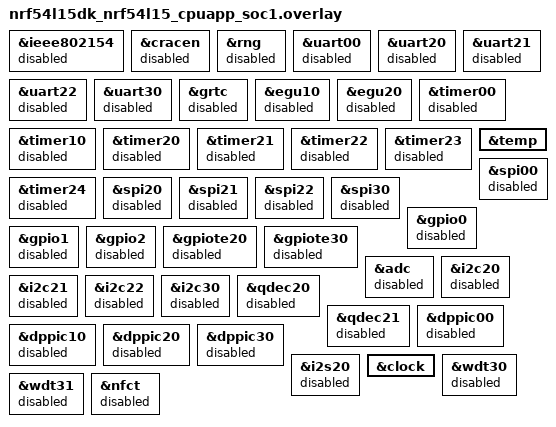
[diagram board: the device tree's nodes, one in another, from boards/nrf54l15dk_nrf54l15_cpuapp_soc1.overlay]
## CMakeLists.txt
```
# list(APPEND OVERLAY_CONFIG "debug.conf")
list(APPEND OVERLAY_CONFIG "dns.conf")
list(APPEND OVERLAY_CONFIG "secret.conf")
list(APPEND OVERLAY_CONFIG "thread-sed.conf")

cmake_minimum_required(VERSION 3.20.0)
find_package(Zephyr REQUIRED HINTS $ENV{ZEPHYR_BASE})

execute_process(COMMAND git describe
                WORKING_DIRECTORY ${CMAKE_CURRENT_SOURCE_DIR}
                OUTPUT_VARIABLE GIT_DESCRIBE
                ERROR_QUIET)
string(STRIP "${GIT_DESCRIBE}" GIT_DESCRIBE)
STRING(REGEX MATCH "[0-9]+\\.[0-9]+\\.[0-9]+"
       VERSION "${GIT_DESCRIBE}")

project(app LANGUAGES C VERSION ${VERSION})

configure_file(app_version.h.in ${CMAKE_BINARY_DIR}/app/include/app_version.h)
zephyr_include_directories(
    ${CMAKE_BINARY_DIR}/app/include
)

target_include_directories(app PRIVATE src)

target_sources(app PRIVATE
        src/main.c)

zephyr_include_directories(
    configuration/${BOARD}
)
```

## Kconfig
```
mainmenu "Thread Button Application"

config APP_MAIN_LOOP_PERIOD_SEC
	int "Main loop period (sec)"
	default 60
	help
	  Main loop period in seconds.

source "Kconfig.zephyr"
```

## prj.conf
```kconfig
CONFIG_APP_MAIN_LOOP_PERIOD_SEC=600

CONFIG_INPUT=y
CONFIG_SERIAL=y

CONFIG_HEAP_MEM_POOL_SIZE=2048

CONFIG_PM_DEVICE=y

CONFIG_MAIN_STACK_SIZE=4096
CONFIG_SYSTEM_WORKQUEUE_STACK_SIZE=2048
CONFIG_LOG_BUFFER_SIZE=16384

CONFIG_CAF=y
CONFIG_CAF_BUTTONS=y
CONFIG_CAF_BUTTONS_DEBOUNCE_INTERVAL=10
CONFIG_CAF_BUTTONS_POLARITY_INVERSED=y
CONFIG_NRFX_GPIOTE_NUM_OF_EVT_HANDLERS=1

CONFIG_MY_MODULE_BASE_RESET=y
CONFIG_MY_MODULE_BASE_UID=y

CONFIG_MY_MODULE_BASE_WATCHDOG=y
CONFIG_MY_MODULE_BASE_WATCHDOG_TIMEOUT_SEC=760

CONFIG_MY_MODULE_BASE_HOME_ASSISTANT=y
CONFIG_MY_MODULE_BASE_HA_DEVICE_NAME="Action Button"
CONFIG_MY_MODULE_BASE_HA_DEV_TYPE_ACTION_BUTTON=y
CONFIG_MY_MODULE_BASE_HA_MQTT_SERVER_HOSTNAME="home.home.arpa"
CONFIG_MY_MODULE_BASE_HA_OT_LATENCY_THREAD_STACK_SIZE=1024

CONFIG_BOARD_ENABLE_DCDC=y

CONFIG_THREAD_NAME=y
CONFIG_EVENTS=y
CONFIG_CONSOLE=y
CONFIG_UART_CONSOLE=y

CONFIG_ENTROPY_NRF5_THR_THRESHOLD=4
CONFIG_ENTROPY_NRF5_ISR_THRESHOLD=12

CONFIG_THREAD_ANALYZER=y
CONFIG_INPUT_LOG_LEVEL_DBG=y
CONFIG_INPUT_THREAD_STACK_SIZE=2048
CONFIG_LOG_SPEED=y
CONFIG_LOG=y
```

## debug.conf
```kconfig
CONFIG_OPENTHREAD_DEBUG=y
# CONFIG_OPENTHREAD_LOG_LEVEL_DEBG=y
# CONFIG_OPENTHREAD_L2_DEBUG=y
# CONFIG_OPENTHREAD_L2_DEBUG_DUMP_15_4=y
```

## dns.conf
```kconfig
CONFIG_DNS_SERVER_IP_ADDRESSES=y
CONFIG_DNS_SERVER1="fd04:2240::1"
```

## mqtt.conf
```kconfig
CONFIG_MQTT_LIB=y
CONFIG_MQTT_KEEPALIVE=600
```

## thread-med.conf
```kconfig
CONFIG_FPU=y

CONFIG_SYSTEM_WORKQUEUE_STACK_SIZE=2048

# CONFIG_NET_TCP_ISN_RFC6528 is not set

CONFIG_OPENTHREAD_CSL_RECEIVER=y
CONFIG_OPENTHREAD_SLAAC=y
CONFIG_OPENTHREAD_CHANNEL=15
CONFIG_OPENTHREAD_NETWORK_NAME="home"
CONFIG_OPENTHREAD_XPANID="42:24:00:00:00:00:10:00"
CONFIG_OPENTHREAD_MTD=y
CONFIG_OPENTHREAD_MTD_SED=y

CONFIG_NETWORKING=y
CONFIG_NET_L2_OPENTHREAD=y

CONFIG_NET_TCP=y
CONFIG_NET_BUF_TX_COUNT=64
CONFIG_NET_LOG=y
```

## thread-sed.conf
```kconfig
CONFIG_OPENTHREAD_CHANNEL=15
CONFIG_OPENTHREAD_NETWORK_NAME="home"
CONFIG_OPENTHREAD_XPANID="42:24:00:00:00:00:10:00"
CONFIG_OPENTHREAD_MTD_SED=y
```

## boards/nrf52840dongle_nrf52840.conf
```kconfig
CONFIG_GPIO=y
CONFIG_SOC_SERIES_NRF52X=y
CONFIG_SOC_NRF52840_QIAA=y
CONFIG_NFCT_PINS_AS_GPIOS=y
CONFIG_ARM_MPU=y
CONFIG_HW_STACK_PROTECTION=y
```

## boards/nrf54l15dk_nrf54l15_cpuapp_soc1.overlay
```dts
/ {

};

&ieee802154 {
	status = "disabled";
};
&cracen {
	status = "disabled";
};
&rng {
	status = "disabled";
};




&uart00 {
	status = "disabled";
};

&uart20 {
	status = "disabled";
};

&uart21 {
	status = "disabled";
};

&uart22 {
	status = "disabled";
};

&uart30 {
	status = "disabled";
};

&grtc {
	status = "disabled";
};

&egu10 {
	status = "disabled";
};

&egu20 {
	status = "disabled";
};

&timer00 {
	status = "disabled";
};

&timer10 {
	status = "disabled";
};

&timer20 {
	status = "disabled";
};

&timer21 {
	status = "disabled";
};

&timer22 {
	status = "disabled";
};

&timer23 {
	status = "disabled";
};

&timer24 {
	status = "disabled";
};

&temp {
	status = "okay";
};

&spi00 {
	status = "disabled";
};

&spi20 {
	status = "disabled";
};

&spi21 {
	status = "disabled";
};

&spi22 {
	status = "disabled";
};

&spi30 {
	status = "disabled";
};

&gpio0 {
	status = "disabled";
};

&gpio1 {
	status = "disabled";
};

&gpio2 {
	status = "disabled";
};

&gpiote20 {
	status = "disabled";
};

&gpiote30 {
	status = "disabled";
};

&adc {
	status = "disabled";
};

&i2c20 {
	status = "disabled";
};

&i2c21 {
	status = "disabled";
};

&i2c22 {
	status = "disabled";
};

&i2c30 {
	status = "disabled";
};

&qdec20 {
	status = "disabled";
};

&qdec21 {
	status = "disabled";
};

&dppic00 {
	status = "disabled";
};

&dppic10 {
	status = "disabled";
};

&dppic20 {
	status = "disabled";
};

&dppic30 {
	status = "disabled";
};

&i2s20 {
       status = "disabled";
};

&clock {
	status = "okay";
};

&wdt30 {
	status = "disabled";
};

&wdt31 {
	status = "disabled";
};

&nfct {
	status = "disabled";
};
```

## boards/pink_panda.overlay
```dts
/* Copyright (c) 2020 Nordic Semiconductor ASA
 *
 * SPDX-License-Identifier: LicenseRef-Nordic-5-Clause
 */

/ {
	/*
	* In some default configurations within the nRF Connect SDK,
	* e.g. on nRF52840, the chosen zephyr,entropy node is &cryptocell.
	* This devicetree overlay ensures that default is overridden wherever it
	* is set, as this application uses the RNG node for entropy exclusively.
	*/
	chosen {
		zephyr,entropy = &rng;
	};
	// buttons: gpio-keys0 {
    //         compatible = "zephyr,gpio-keys";
    //         debounce-interval-ms = <30>;

    //         action_button: button_0 {
    //                 gpios = <&gpio0 25 (GPIO_PULL_UP | GPIO_ACTIVE_LOW)>;
    //                 zephyr,code = <10>;
    //         };
    // };
};
&adc {
	status = "disabled";
};
&uart1 {
	status = "disabled";
};
&pwm0 {
	status = "disabled";
};
&i2c0 {
	status = "disabled";
};
&spi0 {
	status = "disabled";
};
&spi1 {
	status = "disabled";
};
&spi2 {
	status = "disabled";
};
&spi3 {
	status = "disabled";
};
&qspi {
	status = "disabled";
};
&usbd {
	status = "disabled";
};
&gpio0 {
	status = "okay";
};
&gpio1 {
	status = "disabled";
};
&gpiote {
    status = "okay";
};
&ieee802154 {
	status = "okay";
};
```

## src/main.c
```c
#include <app_event_manager.h>
#include <hal/nrf_power.h>
#include <zephyr/drivers/gpio.h>
#include <zephyr/drivers/watchdog.h>
#include <zephyr/input/input.h>
#include <zephyr/pm/device.h>
// There is an include missing in thread_analyzer.h
// Workaround by including it lower.
#include <zephyr/debug/thread_analyzer.h>
#include <zephyr/sys/reboot.h>

#include <zephyr/logging/log.h>
LOG_MODULE_REGISTER(main, LOG_LEVEL_DBG);

#define MODULE main
#include <caf/events/module_state_event.h>
#include <caf/events/button_event.h>

#include <app_version.h>
#include <ha.h>
#include <mqtt.h>
#include <openthread.h>
#include <reset.h>
#include <uid.h>
#include <watchdog.h>



#define RETRY_DELAY_SECONDS			10

#define MAIN_LOOP_PERIOD_SECONDS		CONFIG_APP_MAIN_LOOP_PERIOD_SEC
#define NUMBER_OF_LOOP_RUN_ANALYSIS		((2 * MAIN_LOOP_PERIOD_SECONDS) / MAIN_LOOP_PERIOD_SECONDS)
#define NUMBER_OF_LOOP_RESET_WATCHDOG_SENSOR	((2 * MAIN_LOOP_PERIOD_SECONDS) / MAIN_LOOP_PERIOD_SECONDS)

#define SUSPEND_CONSOLE				1

#define ERROR_BOOT_TOKEN			(uint8_t)0x38


// static const struct device *const buttons_dev = DEVICE_DT_GET(DT_NODELABEL(buttons));
static bool ready = false;

static struct ha_sensor watchdog_triggered_sensor = {
	.type = HA_BINARY_SENSOR_TYPE,
	.name = "Watchdog",
	.device_class = "problem",
	.retain = true,
};

static struct ha_trigger trigger1 = {
	.type = "button_short_press",
	.subtype = "button_1",
};


int main(void)
{
	const struct device *wdt = DEVICE_DT_GET(DT_NODELABEL(wdt0));
	const struct device *cons = DEVICE_DT_GET(DT_CHOSEN(zephyr_console));

	int ret;
	int main_wdt_chan_id = -1, mqtt_wdt_chan_id = -1;
	uint32_t reset_cause;
	bool fast_boot = false;

	uint32_t main_loop_counter = 0;


	ret = watchdog_new_channel(wdt, &main_wdt_chan_id);
	if (ret < 0) {
		LOG_ERR("Could allocate main watchdog channel");
		return ret;
	}

	ret = watchdog_new_channel(wdt, &mqtt_wdt_chan_id);
	if (ret < 0) {
		LOG_ERR("Could allocate main watchdog channel");
		return ret;
	}

	ret = watchdog_start(wdt);
	if (ret < 0) {
		LOG_ERR("Could allocate start watchdog");
		return ret;
	}

	LOG_INF("\n\n🚀 MAIN START (%s) 🚀\n", APP_VERSION_FULL);

	reset_cause = show_reset_cause();
	clear_reset_cause();

	if (is_reset_cause_watchdog(reset_cause)
	    || is_reset_cause_button(reset_cause)) {
		ret = openthread_erase_persistent_info();
		if (ret < 0) {
			LOG_WRN("Could not erase openthread info");
		}
	}
	else if (is_reset_cause_software(reset_cause)
		 && nrf_power_gpregret_get(NRF_POWER, 0) == ERROR_BOOT_TOKEN) {
		LOG_INF("🔥 Fast boot!");
		fast_boot = true;
	}

	ret = openthread_my_start();
	if (ret < 0) {
		LOG_ERR("Could not start openthread");
		return ret;
	}

	ret = uid_init();
	if (ret < 0) {
		LOG_ERR("Could not init uid module");
		return ret;
	}

	ret = uid_generate_unique_id(watchdog_triggered_sensor.unique_id,
				     sizeof(watchdog_triggered_sensor.unique_id),
				     "nrf52840", "wdt",
				     uid_get_device_id());
	if (ret < 0) {
		LOG_ERR("Could not generate watchdog unique id");
		return ret;
	}

	if (app_event_manager_init()) {
		LOG_ERR("Event manager not initialized");
	} else {
		module_set_state(MODULE_STATE_READY);
	}

	LOG_INF("💤 waiting for openthread to be ready");
	openthread_wait_for_ready();
	// Something else is not ready, not sure what
	k_sleep(K_MSEC(100));

	mqtt_watchdog_init(wdt, mqtt_wdt_chan_id);
	ha_start(uid_get_device_id(), fast_boot);

	ha_register_sensor_retry(&watchdog_triggered_sensor, RETRY_DELAY_SECONDS);
	ha_register_trigger_retry(&trigger1, RETRY_DELAY_SECONDS);

	if (!fast_boot) {
		ha_set_binary_sensor_state(&watchdog_triggered_sensor,
					   is_reset_cause_watchdog(reset_cause));
		ha_send_binary_sensor_retry(&watchdog_triggered_sensor,
					    RETRY_DELAY_SECONDS);
	}

	ready = true;

	LOG_INF("🎉 init done 🎉");

#if SUSPEND_CONSOLE
	pm_device_action_run(cons, PM_DEVICE_ACTION_SUSPEND);
#endif

	while(1) {
		LOG_INF("🗨️  main loop counter: %d", main_loop_counter);
		if (main_loop_counter % NUMBER_OF_LOOP_RUN_ANALYSIS == 0) {
#if !(SUSPEND_CONSOLE)
			thread_analyzer_print();
#endif
		}

		if (main_loop_counter >= NUMBER_OF_LOOP_RESET_WATCHDOG_SENSOR &&
		    ha_get_binary_sensor_state(&watchdog_triggered_sensor) == true) {
			ha_set_binary_sensor_state(&watchdog_triggered_sensor, false);
			ha_send_binary_sensor_retry(&watchdog_triggered_sensor,
						    RETRY_DELAY_SECONDS);
		}

		if (main_loop_counter == 0) {
			// We set the device online a little after sensor
			// registrations so HA gets time to process the sensor
			// registrations first before setting the entities online
			LOG_INF("💤 waiting for HA to process registration");
			k_sleep(K_SECONDS(5));

			ha_set_online_retry(RETRY_DELAY_SECONDS);
		}

		// Epilogue

		main_loop_counter += 1;

		LOG_INF("🦴 feed watchdog");
		wdt_feed(wdt, main_wdt_chan_id);

		LOG_INF("💤 end of main loop");
		k_sleep(K_SECONDS(MAIN_LOOP_PERIOD_SECONDS));
	}

	return 0;
}

// static void event_handler(struct input_event *evt)
// {
// 	int ret;

// 	LOG_INF("GPIO_KEY %s pressed, zephyr_code=%u, value=%d",
// 		 evt->dev->name, evt->code, evt->value);

// 	// Do nothing on release
// 	if (!evt->value) {
// 		return;
// 	}

// 	if (!ready) {
// 		return;
// 	}

// 	ret = ha_send_trigger_event(&trigger1);
// 	if (ret < 0) {
// 		LOG_ERR("could not send button state");
// 		// modules/lib/matter/src/platform/nrfconnect/Reboot.cpp
// 		// zephyr/soc/arm/nordic_nrf/nrf52/soc.c
// 		sys_reboot(ERROR_BOOT_TOKEN);
// 	}
// }

// Upcoming API: INPUT_CALLBACK_DEFINE()
// INPUT_LISTENER_CB_DEFINE(buttons_dev, event_handler);


static bool event_handler(const struct app_event_header *eh)
{
	int ret;
	const struct button_event *evt;

	if (!ready) {
		goto out;
	}

	if (is_button_event(eh)) {
		evt = cast_button_event(eh);

		if (evt->pressed) {
			ret = ha_send_trigger_event(&trigger1);
			if (ret < 0) {
				LOG_ERR("could not send button state");
				// modules/lib/matter/src/platform/nrfconnect/Reboot.cpp
				// zephyr/soc/arm/nordic_nrf/nrf52/soc.c
				sys_reboot(ERROR_BOOT_TOKEN);
			}
		}
	}

out:
	return true;
}

APP_EVENT_LISTENER(MODULE, event_handler);
APP_EVENT_SUBSCRIBE(MODULE, button_event);
```

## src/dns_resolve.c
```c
#include <openthread/thread.h>
#include <zephyr/net/openthread.h>
#include <zephyr/net/dns_resolve.h>

#include <zephyr/logging/log.h>
LOG_MODULE_REGISTER(dns_resolve, LOG_LEVEL_DBG);

#include "openthread.h"


#define DNS_TIMEOUT (2 * MSEC_PER_SEC)

char dns_resolve_last_resolve_addr[NET_IPV6_ADDR_LEN];
bool dns_resolve_finished;
bool dns_resolve_success;


static void dns_result_cb(enum dns_resolve_status status,
		   struct dns_addrinfo *info,
		   void *user_data)
{
	char *hr_family;
	void *addr;

	k_sleep(K_MSEC(50));
	openthread_set_normal_latency();

	switch (status) {
	case DNS_EAI_CANCELED:
		LOG_INF("DNS query was canceled");
		goto out;
	case DNS_EAI_FAIL:
		LOG_INF("DNS resolve failed");
		goto out;
	case DNS_EAI_NODATA:
		LOG_INF("Cannot resolve address");
		goto out;
	case DNS_EAI_ALLDONE:
		LOG_INF("DNS resolving finished");
		goto out;
	case DNS_EAI_INPROGRESS:
		break;
	default:
		LOG_INF("DNS resolving error (%d)", status);
		goto out;
	}

	if (!info) {
		goto out;
	}

	if (info->ai_family == AF_INET) {
		hr_family = "IPv4";
		addr = &net_sin(&info->ai_addr)->sin_addr;
		LOG_ERR("We need an ipv6 address but received ipv4");
	} else if (info->ai_family == AF_INET6) {
		hr_family = "IPv6";
		addr = (char *)&net_sin6(&info->ai_addr)->sin6_addr;
	} else {
		LOG_ERR("Invalid IP address family %d", info->ai_family);
		goto out;
	}

	LOG_INF("%s %s address: %s", user_data ? (char *)user_data : "<null>",
		hr_family,
		net_addr_ntop(info->ai_family, addr,
			dns_resolve_last_resolve_addr,
			sizeof(dns_resolve_last_resolve_addr)));

	dns_resolve_success = true;
out:
	dns_resolve_finished = true;
}

void dns_resolve_do_ipv6_lookup(void)
{
	static const char *query = "home.home.arpa";
	static uint16_t dns_id;
	int ret;

	dns_resolve_finished = false;
	dns_resolve_success = false;

	openthread_set_low_latency();

	ret = dns_get_addr_info(query,
				DNS_QUERY_TYPE_AAAA,
				&dns_id,
				dns_result_cb,
				(void *)query,
				DNS_TIMEOUT);
	if (ret < 0) {
		LOG_ERR("Cannot resolve IPv6 address (%d)", ret);
		dns_resolve_finished = true;
		openthread_set_normal_latency();
		return;
	}

	LOG_DBG("DNS id %u", dns_id);
}
```

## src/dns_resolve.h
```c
#ifndef DNS_RESOLVE_H_
#define DNS_RESOLVE_H_

#include <zephyr/net/net_ip.h>


extern char dns_resolve_last_resolve_addr[NET_IPV6_ADDR_LEN];
extern bool dns_resolve_finished;
extern bool dns_resolve_success;

void dns_resolve_do_ipv6_lookup(void);

#endif /* DNS_RESOLVE_H_ */
```

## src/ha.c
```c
// MQTT device data
// -----------------------------------------------------------------------------
// ~ = CONFIG_APP_DEV_TYPE_* / device_id_hex_string (MQTT_BASE_PATH_FORMAT_STRING)
// availability_topic = ~/available
// state_topic = ~ / <sensor|binary_sensor|trigger> / sensor->unique_id /state

// MQTT Home Assistant config
// -----------------------------------------------------------------------------
// homeassistant / <sensor|binary_sensor|trigger> / conf->unique_id /config

#include <zephyr/logging/log.h>
LOG_MODULE_REGISTER(home_assistant, LOG_LEVEL_DBG);

#include <zephyr/data/json.h>

#include <stdio.h>
#include <stdlib.h>
#include <app_version.h>

#include "ha.h"
#include "mqtt.h"


#define JSON_CONFIG_BUFFER_SIZE		1024
#define UNIQUE_ID_BUFFER_SIZE		64

#if defined(CONFIG_APP_DEV_TYPE_AIR_QUALITY)
#define MQTT_BASE_PATH_FORMAT_STRING "air_quality/%s"
#elif defined(CONFIG_APP_DEV_TYPE_ACTION_BUTTON)
#define MQTT_BASE_PATH_FORMAT_STRING "action_button/%s"
#else
#error "No device type defined"
#endif

#define LAST_WILL_TOPIC_FORMAT_STRING MQTT_BASE_PATH_FORMAT_STRING "/available"
#if defined(CONFIG_APP_USE_TEST_DISCOVERY_TOPIC)
#define DISCOVERY_TOPIC_FORMAT_STRING		"test/%s/%s/config"
#define DISCOVERY_TOPIC_TRIGGER_FORMAT_STRING	"test/%s/%s/%s_%s/config"
#else
#define DISCOVERY_TOPIC_FORMAT_STRING		"homeassistant/%s/%s/config"
#define DISCOVERY_TOPIC_TRIGGER_FORMAT_STRING	"homeassistant/%s/%s/%s_%s/config"
#endif

#define DEVICE_CONFIG {						\
	.identifiers = device_id_hex_string,				\
	.name = CONFIG_APP_DEVICE_NAME " - " CONFIG_APP_DEVICE_NICKNAME,	\
	.sw_version = APP_VERSION_FULL,					\
	.hw_version = "rev1",						\
	.model = "Gold",						\
	.manufacturer = "François Gervais",				\
}

struct ha_device {
	const char *identifiers;
	const char *name;
	const char *sw_version;
	const char *hw_version;
	const char *model;
	const char *manufacturer;
};

struct ha_sensor_config {
	const char *base_path;
	const char *name;
	const char *unique_id;
	const char *object_id;
	const char *device_class;
	const char *state_class;
	const char *unit_of_measurement;
	int suggested_display_precision;
	const char *availability_topic;
	const char *state_topic;
	struct ha_device dev;
};

struct ha_trigger_config {
	const char *automation_type;
	const char *payload;
	const char *topic;
	const char *type;
	const char *subtype;
	struct ha_device dev;
};


static const char *device_id_hex_string;
static char mqtt_base_path[HA_TOPIC_BUFFER_SIZE];

static char last_will_topic[HA_TOPIC_BUFFER_SIZE];
static const char *last_will_message = "offline";

static bool inhibit_discovery_mode;


static const struct json_obj_descr device_descr[] = {
	JSON_OBJ_DESCR_PRIM(struct ha_device, identifiers,	JSON_TOK_STRING),
	JSON_OBJ_DESCR_PRIM(struct ha_device, name,	 	JSON_TOK_STRING),
	JSON_OBJ_DESCR_PRIM(struct ha_device, sw_version,	JSON_TOK_STRING),
	JSON_OBJ_DESCR_PRIM(struct ha_device, hw_version,	JSON_TOK_STRING),
	JSON_OBJ_DESCR_PRIM(struct ha_device, model,	 	JSON_TOK_STRING),
	JSON_OBJ_DESCR_PRIM(struct ha_device, manufacturer, 	JSON_TOK_STRING),
};

static const struct json_obj_descr sensor_config_descr[] = {
	JSON_OBJ_DESCR_PRIM_NAMED(struct ha_sensor_config, "~", base_path,	JSON_TOK_STRING),
	JSON_OBJ_DESCR_PRIM(struct ha_sensor_config, name,			JSON_TOK_STRING),
	JSON_OBJ_DESCR_PRIM(struct ha_sensor_config, unique_id,			JSON_TOK_STRING),
	JSON_OBJ_DESCR_PRIM(struct ha_sensor_config, object_id,			JSON_TOK_STRING),
	JSON_OBJ_DESCR_PRIM(struct ha_sensor_config, device_class,		JSON_TOK_STRING),
	JSON_OBJ_DESCR_PRIM(struct ha_sensor_config, state_class,		JSON_TOK_STRING),
	JSON_OBJ_DESCR_PRIM(struct ha_sensor_config, unit_of_measurement,	JSON_TOK_STRING),
	JSON_OBJ_DESCR_PRIM(struct ha_sensor_config, suggested_display_precision, JSON_TOK_NUMBER),
	JSON_OBJ_DESCR_PRIM(struct ha_sensor_config, availability_topic,	JSON_TOK_STRING),
	JSON_OBJ_DESCR_PRIM(struct ha_sensor_config, state_topic,		JSON_TOK_STRING),
	JSON_OBJ_DESCR_OBJECT(struct ha_sensor_config, dev, device_descr),
};

static const struct json_obj_descr binary_sensor_config_descr[] = {
	JSON_OBJ_DESCR_PRIM_NAMED(struct ha_sensor_config, "~", base_path,	JSON_TOK_STRING),
	JSON_OBJ_DESCR_PRIM(struct ha_sensor_config, name,			JSON_TOK_STRING),
	JSON_OBJ_DESCR_PRIM(struct ha_sensor_config, unique_id,			JSON_TOK_STRING),
	JSON_OBJ_DESCR_PRIM(struct ha_sensor_config, object_id,			JSON_TOK_STRING),
	JSON_OBJ_DESCR_PRIM(struct ha_sensor_config, device_class,		JSON_TOK_STRING),
	JSON_OBJ_DESCR_PRIM(struct ha_sensor_config, availability_topic,	JSON_TOK_STRING),
	JSON_OBJ_DESCR_PRIM(struct ha_sensor_config, state_topic,		JSON_TOK_STRING),
	JSON_OBJ_DESCR_OBJECT(struct ha_sensor_config, dev, device_descr),
};

static const struct json_obj_descr trigger_config_descr[] = {
	JSON_OBJ_DESCR_PRIM(struct ha_trigger_config, automation_type,		JSON_TOK_STRING),
	JSON_OBJ_DESCR_PRIM(struct ha_trigger_config, payload,			JSON_TOK_STRING),
	JSON_OBJ_DESCR_PRIM(struct ha_trigger_config, topic,			JSON_TOK_STRING),
	JSON_OBJ_DESCR_PRIM(struct ha_trigger_config, type,			JSON_TOK_STRING),
	JSON_OBJ_DESCR_PRIM(struct ha_trigger_config, subtype,			JSON_TOK_STRING),
	JSON_OBJ_DESCR_OBJECT(struct ha_trigger_config, dev, device_descr),
};

// <discovery_prefix>/<component>/[<node_id>/]<object_id>/config
//
// Best practice for entities with a unique_id is to set <object_id> to
// unique_id and omit the <node_id>.
// https://www.home-assistant.io/integrations/mqtt/#discovery-topic
static int ha_send_sensor_discovery(const char *sensor_type,
			     struct ha_sensor_config *conf)
{
	int ret;
	char json_config[JSON_CONFIG_BUFFER_SIZE];
	char discovery_topic[HA_TOPIC_BUFFER_SIZE];

	snprintf(discovery_topic, sizeof(discovery_topic),
		 DISCOVERY_TOPIC_FORMAT_STRING,
		 sensor_type, conf->unique_id);

	LOG_DBG("discovery topic: %s", discovery_topic);

	if (strcmp(sensor_type, "sensor") == 0) {
		ret = json_obj_encode_buf(
			sensor_config_descr, ARRAY_SIZE(sensor_config_descr),
			conf, json_config, sizeof(json_config));
		if (ret < 0) {
			LOG_ERR("Could not encode JSON (%d)", ret);
			return ret;
		}
	}
	else if (strcmp(sensor_type, "binary_sensor") == 0) {
		ret = json_obj_encode_buf(
			binary_sensor_config_descr,
			ARRAY_SIZE(binary_sensor_config_descr),
			conf, json_config, sizeof(json_config));
		if (ret < 0) {
			LOG_ERR("Could not encode JSON (%d)", ret);
			return ret;
		}
	}

	LOG_DBG("payload: %s", json_config);

	ret = mqtt_publish_to_topic(discovery_topic, json_config, true);
	if (ret < 0) {
		LOG_ERR("Count not publish to topic");
		return ret;
	}

	return 0;
}

static int ha_send_trigger_discovery(struct ha_trigger_config *conf)
{
	int ret;
	char json_config[JSON_CONFIG_BUFFER_SIZE];
	char discovery_topic[HA_TOPIC_BUFFER_SIZE];

	snprintf(discovery_topic, sizeof(discovery_topic),
		 DISCOVERY_TOPIC_TRIGGER_FORMAT_STRING,
		 "device_automation", device_id_hex_string,
		 conf->type, conf->subtype);

	LOG_DBG("discovery topic: %s", discovery_topic);

	ret = json_obj_encode_buf(
		trigger_config_descr, ARRAY_SIZE(trigger_config_descr),
		conf, json_config, sizeof(json_config));
	if (ret < 0) {
		LOG_ERR("Could not encode JSON (%d)", ret);
		return ret;
	}

	LOG_DBG("payload: %s", json_config);

	ret = mqtt_publish_to_topic(discovery_topic, json_config, true);
	if (ret < 0) {
		LOG_ERR("Count not publish to topic");
		return ret;
	}

	return 0;
}

int ha_start(const char *device_id, bool inhibit_discovery)
{
	int ret;

	device_id_hex_string = device_id;
	inhibit_discovery_mode = inhibit_discovery;

	ret = snprintf(mqtt_base_path, sizeof(mqtt_base_path),
		 MQTT_BASE_PATH_FORMAT_STRING, device_id_hex_string);
	if (ret < 0 && ret >= sizeof(mqtt_base_path)) {
		LOG_ERR("Could not set mqtt_base_path");
		return -ENOMEM;
	}

	ret = snprintf(last_will_topic, sizeof(last_will_topic),
		 LAST_WILL_TOPIC_FORMAT_STRING, device_id_hex_string);
	if (ret < 0 && ret >= sizeof(last_will_topic)) {
		LOG_ERR("Could not set last_will_topic");
		return -ENOMEM;
	}

	ret = mqtt_init(device_id_hex_string, last_will_topic, last_will_message);
	if (ret < 0) {
		LOG_ERR("could initialize MQTT");
		return ret;
	}

	return 0;
}

int ha_set_online()
{
	int ret;

	ret = mqtt_publish_to_topic(last_will_topic, "online", true);
	if (ret < 0) {
		LOG_ERR("Count not publish to topic");
		return ret;
	}

	return 0;
}

// `object_id` = `unique id`
//
// `object_id` is set to `unique id` in order to maintain full `name` flexibility
// as by default, the `entity_id` is generated from the `name` if defined and
// `entity_id` has strict character requirements.
//
// Setting the `object_id` allows HA to use it instead of the name to
// generate the `entity_id` thus allowing name to use characters unallowed
// in an `entity_id`.
//
// https://github.com/home-assistant/core/issues/4628#:~:text=Description%20of%20problem%3A%20In%20case%20device%20has%20no%20English%20characters%20in%20the%20name%20HA%20will%20generate%20an%20empty%20entity_id%20and%20it%20will%20not%20be%20possible%20to%20access%20the%20device%20from%20HA.
// 
// object_id: Used instead of name for automatic generation of entity_id
//   https://www.home-assistant.io/integrations/sensor.mqtt/#object_id
//
// Best practice for entities with a unique_id is to set <object_id> to unique_id
//   https://www.home-assistant.io/integrations/mqtt/#discovery-messages
//
// MQTT sensor example:
// https://community.home-assistant.io/t/unique-id-with-mqtt-sensor-not-working/564315/8
//
// Other usefull links:
// https://community.home-assistant.io/t/unique-id-and-object-id-are-being-ignored-in-my-mqtt-sensor/397368/14
// https://community.home-assistant.io/t/wth-are-there-unique-id-and-entity-id/467623/9
int ha_register_sensor(struct ha_sensor *sensor)
{
	int ret;
	char brief_state_topic[HA_TOPIC_BUFFER_SIZE];
	struct ha_sensor_config ha_sensor_config = {
		.base_path = mqtt_base_path,
		.name = sensor->name,
		.unique_id = sensor->unique_id,
		.object_id = sensor->unique_id,
		.device_class = sensor->device_class,
		.state_class = sensor->state_class,
		.unit_of_measurement = sensor->unit_of_measurement,
		.suggested_display_precision = sensor->suggested_display_precision,
		.availability_topic = "~/available",
		.state_topic = brief_state_topic,
		.dev = DEVICE_CONFIG,
	};

	LOG_INF("📝 registering sensor: %s", sensor->unique_id);

	ret = snprintf(brief_state_topic, sizeof(brief_state_topic),
		       "~/%s/%s/state",
		       sensor->type, sensor->unique_id);
	if (ret < 0 && ret >= sizeof(brief_state_topic)) {
		LOG_ERR("Could not set brief_state_topic");
		return -ENOMEM;
	}

	ret = snprintf(sensor->full_state_topic, sizeof(sensor->full_state_topic),
		 "%s%s",
		 mqtt_base_path,
		 brief_state_topic + 1);
	if (ret < 0 && ret >= sizeof(brief_state_topic)) {
		LOG_ERR("Could not set full_state_topic");
		return -ENOMEM;
	}

	if (!inhibit_discovery_mode) {
		LOG_INF("📖 send discovery");
		ret = ha_send_sensor_discovery(sensor->type, &ha_sensor_config);
		if (ret < 0) {
			LOG_ERR("Could not send discovery");
			return ret;
		}
	}

	return 0;
}

int ha_add_sensor_reading(struct ha_sensor *sensor, double value)
{
	sensor->total_value += value;
	sensor->number_of_values += 1;

	return 0;
}

int ha_set_binary_sensor_state(struct ha_sensor *sensor, bool state)
{
	sensor->binary_state = state;

	return 0;
}

bool ha_get_binary_sensor_state(struct ha_sensor *sensor)
{
	return sensor->binary_state;
}

int ha_send_sensor_value(struct ha_sensor *sensor)
{
	int ret;
	char value_string[16];

	if (sensor->number_of_values == 0) {
		goto out;
	}

	ret = snprintf(value_string, sizeof(value_string),
		       "%g",
		       sensor->total_value / sensor->number_of_values);
	if (ret < 0 && ret >= sizeof(value_string)) {
		LOG_ERR("Could not set value_string");
		return -ENOMEM;
	}

	ret = mqtt_publish_to_topic(sensor->full_state_topic,
		value_string, sensor->retain);
	if (ret < 0) {
		LOG_ERR("Count not publish to topic");
		return ret;
	}

	sensor->total_value = 0;
	sensor->number_of_values = 0;

out:
	return 0;
}

int ha_send_binary_sensor_state(struct ha_sensor *sensor)
{
	int ret;

	ret = mqtt_publish_to_topic(sensor->full_state_topic,
		sensor->binary_state ? "ON" : "OFF", sensor->retain);
	if (ret < 0) {
		LOG_ERR("Count not publish to topic");
		return ret;
	}

	return 0;
}

int ha_register_trigger(struct ha_trigger *trigger)
{
	int ret;
	struct ha_trigger_config ha_trigger_config = {
		.automation_type = "trigger",
		.payload = "PRESS",
		.topic = trigger->full_topic,
		.type = trigger->type,
		.subtype = trigger->subtype,
		.dev = DEVICE_CONFIG,
	};

	LOG_INF("📝 registering trigger: %s", trigger->type);

	ret = snprintf(trigger->full_topic, sizeof(trigger->full_topic),
		 "%s/%s/%s_%s/action",
		 mqtt_base_path,
		 "trigger", trigger->type, trigger->subtype);
	if (ret < 0 && ret >= sizeof(trigger->full_topic)) {
		LOG_ERR("Could not set full_topic");
		return -ENOMEM;
	}

	if (!inhibit_discovery_mode) {
		LOG_INF("📖 send discovery");
		ret = ha_send_trigger_discovery(&ha_trigger_config);
		if (ret < 0) {
			LOG_ERR("Could not send discovery");
			return ret;
		}
	}

	return 0;
}

int ha_send_trigger_event(struct ha_trigger *trigger)
{
	int ret;

	ret = mqtt_publish_to_topic(trigger->full_topic,
		"PRESS", false);
	if (ret < 0) {
		LOG_ERR("Count not publish to topic");
		return ret;
	}

	return 0;
}
```

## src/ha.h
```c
#ifndef HA_H_
#define HA_H_

#include <uid.h>

#define HA_TOPIC_BUFFER_SIZE		128

#define HA_SENSOR_TYPE				"sensor"
#define HA_BINARY_SENSOR_TYPE		"binary_sensor"

struct ha_sensor {
	// Set by user
	const char *type;
	const char *name;
	char unique_id[UID_UNIQUE_ID_STRING_SIZE];
	const char *device_class;
	const char *state_class;
	const char *unit_of_measurement;
	int suggested_display_precision;
	bool retain;

	// Internal use
	double total_value;
	int number_of_values;
	bool binary_state;

	char full_state_topic[HA_TOPIC_BUFFER_SIZE];
};

struct ha_trigger {
	// Set by user
	const char *type;
	const char *subtype;

	char full_topic[HA_TOPIC_BUFFER_SIZE];
};

int ha_start(const char *device_id, bool inhibit_discovery);
int ha_set_online();

int ha_init_sensor(struct ha_sensor *);
int ha_init_binary_sensor(struct ha_sensor *);

int ha_register_sensor(struct ha_sensor *);

int ha_add_sensor_reading(struct ha_sensor *, double value);
int ha_set_binary_sensor_state(struct ha_sensor *, bool state);

bool ha_get_binary_sensor_state(struct ha_sensor *);

int ha_send_sensor_value(struct ha_sensor *);
int ha_send_binary_sensor_state(struct ha_sensor *);

int ha_register_trigger(struct ha_trigger *);
int ha_send_trigger_event(struct ha_trigger *);

#endif /* HA_H_ */
```

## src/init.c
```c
#include <zephyr/drivers/watchdog.h>
#include <zephyr/kernel.h>

#include <zephyr/logging/log.h>
LOG_MODULE_REGISTER(init, LOG_LEVEL_DBG);

#include "init.h"


static int watchdog_new_channel(const struct device *wdt)
{
	int ret;

	struct wdt_timeout_cfg wdt_config = {
		.window.min = 0,
		.window.max = CONFIG_APP_WATCHDOG_TIMEOUT_SEC * MSEC_PER_SEC,
		.callback = NULL,
		.flags = WDT_FLAG_RESET_SOC,
	};

	ret = wdt_install_timeout(wdt, &wdt_config);
	if (ret < 0) {
		LOG_ERR("watchdog install error");
	}

	return ret;
}

int init_watchdog(const struct device *wdt,
		  int *main_channel_id, int *mqtt_channel_id)
{
	int ret;

	if (!device_is_ready(wdt)) {
		LOG_ERR("%s: device not ready", wdt->name);
		return -ENODEV;
	}

	ret = watchdog_new_channel(wdt);
	if (ret < 0) {
		LOG_ERR("Could not create a new watchdog channel");
		return ret;
	}

	*main_channel_id = ret;
	LOG_INF("main watchdog channel id: %d", *main_channel_id);

	ret = watchdog_new_channel(wdt);
	if (ret < 0) {
		LOG_ERR("Could not create a new watchdog channel");
		return ret;
	}

	*mqtt_channel_id = ret;
	LOG_INF("mqtt watchdog channel id: %d", *mqtt_channel_id);

	ret = wdt_setup(wdt, WDT_OPT_PAUSE_HALTED_BY_DBG);
	if (ret < 0) {
		LOG_ERR("watchdog setup error");
		return 0;
	}

	LOG_INF("🐶 watchdog started!");

	return 0;
}
```

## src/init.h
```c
#ifndef INIT_H_
#define INIT_H_

int init_watchdog(const struct device *wdt,
		  int *main_channel_id, int *mqtt_channel_id);

#endif /* INIT_H_ */
```

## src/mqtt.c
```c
#include <zephyr/drivers/watchdog.h>
#include <zephyr/net/mqtt.h>
#include <zephyr/net/socket.h>
#include <zephyr/random/rand32.h>

#include <zephyr/logging/log.h>
LOG_MODULE_REGISTER(mqtt, LOG_LEVEL_DBG);

#include "mqtt.h"
#include "openthread.h"


#define MQTT_EVENT_CONNECTED		BIT(0)


static uint8_t rx_buffer[CONFIG_APP_MQTT_BUFFER_SIZE];
static uint8_t tx_buffer[CONFIG_APP_MQTT_BUFFER_SIZE];

static struct mqtt_client client_ctx;

static struct mqtt_topic last_will_topic;
static struct mqtt_utf8 last_will_message;

static struct sockaddr_storage broker;

/* Socket Poll */
static struct zsock_pollfd fds[1];
static int nfds;

static const char *device_id;

static const struct mqtt_subscription *subscriptions;
static size_t number_of_subscriptions;

static struct k_work_delayable keepalive_work;

#if defined(CONFIG_DNS_RESOLVER)
static struct zsock_addrinfo hints;
static struct zsock_addrinfo *haddr;
#endif

static const struct device *wdt;
static int wdt_channel_id;

static K_EVENT_DEFINE(mqtt_events);


static int connect_to_server(void);
static void keepalive(struct k_work *work);
static void mqtt_event_handler(struct mqtt_client *const client,
			       const struct mqtt_evt *evt);


static void prepare_fds(struct mqtt_client *client)
{
	fds[0].fd = client->transport.tcp.sock;
	fds[0].events = ZSOCK_POLLIN;
	nfds = 1;
}

static void clear_fds(void)
{
	nfds = 0;
}

static int poll_socket(int timeout)
{
	int rc = -EINVAL;

	if (nfds <= 0) {
		return rc;
	}

	// Peer disconnect counts as a read event.
	// https://stackoverflow.com/questions/17692447/does-poll-system-call-know-if-remote-socket-closed-or-disconnected#:~:text=Peer%20disconnect%20counts%20as%20a%20read%20event.
	rc = zsock_poll(fds, nfds, timeout);
	if (rc < 0) {
		LOG_ERR("poll error: %d", errno);
		return -errno;
	}

	return rc;
}

static void broker_init(void)
{
	struct sockaddr_in6 *broker6 = (struct sockaddr_in6 *)&broker;

	broker6->sin6_family = AF_INET6;
	broker6->sin6_port = htons(CONFIG_APP_MQTT_SERVER_PORT);

#if defined(CONFIG_DNS_RESOLVER)
	net_ipaddr_copy(&broker6->sin6_addr,
			&net_sin6(haddr->ai_addr)->sin6_addr);
#else
	zsock_inet_pton(AF_INET6, CONFIG_APP_MQTT_SERVER_ADDR, &broker6->sin_addr);
#endif

	k_work_init_delayable(&keepalive_work, keepalive);
}

static void client_init(struct mqtt_client *client)
{
	mqtt_client_init(client);

	broker_init();

	client->broker = &broker;
	client->evt_cb = mqtt_event_handler;

	// The MQTT server will remember our subscriptions based on this ID
	// if ever we get disconnected.
	// 
	// https://stackoverflow.com/questions/75927301/why-should-the-clients-of-mqtt-choose-their-own-id
	// https://docs.zephyrproject.org/latest/connectivity/networking/api/mqtt.html#c.mqtt_client.clean_session
	client->client_id.utf8 = (uint8_t *)device_id;
	client->client_id.size = strlen(device_id);

	LOG_DBG("client id: %s", device_id);

	client->password = NULL;
	client->user_name = NULL;

	client->protocol_version = MQTT_VERSION_3_1_1;

	client->rx_buf = rx_buffer;
	client->rx_buf_size = sizeof(rx_buffer);
	client->tx_buf = tx_buffer;
	client->tx_buf_size = sizeof(tx_buffer);

	client->transport.type = MQTT_TRANSPORT_NON_SECURE;

	client->will_topic = &last_will_topic;
	client->will_message = &last_will_message;
	client->will_retain = 1;
}

static bool is_mqtt_connected(void)
{
	// return k_event_test(&mqtt_events, MQTT_EVENT_CONNECTED);
	return k_event_wait(&mqtt_events, MQTT_EVENT_CONNECTED, false, K_NO_WAIT);
}

static void mqtt_connected(void)
{
	k_event_set(&mqtt_events, MQTT_EVENT_CONNECTED);
}

static void mqtt_disconnected(void)
{
	k_event_clear(&mqtt_events, MQTT_EVENT_CONNECTED);
	clear_fds();
}

static void wait_for_mqtt_connected(void)
{
	k_event_wait(&mqtt_events, MQTT_EVENT_CONNECTED, false, K_FOREVER);
}

static void mqtt_event_handler(struct mqtt_client *const client,
		      const struct mqtt_evt *evt)
{
	uint8_t data[33];
	int len;
	int bytes_read;

	switch (evt->type) {
	case MQTT_EVT_SUBACK:
		openthread_request_normal_latency("MQTT_EVT_SUBACK");

		LOG_INF("SUBACK packet id: %u", evt->param.suback.message_id);
		break;

	case MQTT_EVT_UNSUBACK:
		openthread_request_normal_latency("MQTT_EVT_UNSUBACK");

		LOG_INF("UNSUBACK packet id: %u", evt->param.suback.message_id);
		break;

	case MQTT_EVT_CONNACK:
		openthread_request_normal_latency("MQTT_EVT_CONNACK");

		if (evt->result) {
			LOG_ERR("MQTT connect failed %d", evt->result);
			break;
		}

		LOG_INF("MQTT client connected!");
		mqtt_connected();
		break;

	case MQTT_EVT_DISCONNECT:
		openthread_force_normal_latency("MQTT_EVT_DISCONNECT");

		LOG_INF("MQTT client disconnected %d", evt->result);

		// We let keepalive running so on next ping it will reconnect
		// so we will be back online and the watchdog will get fed.
		mqtt_disconnected();
		break;

	case MQTT_EVT_PUBACK:
		openthread_request_normal_latency("MQTT_EVT_PUBACK");

		if (evt->result) {
			LOG_ERR("MQTT PUBACK error %d", evt->result);
			break;
		}

		LOG_INF("PUBACK packet id: %u", evt->param.puback.message_id);
		break;

	case MQTT_EVT_PUBLISH:
		len = evt->param.publish.message.payload.len;

		LOG_INF("📨 MQTT publish received %d, %d bytes", evt->result, len);
		LOG_INF("   ├── id: %d, qos: %d", evt->param.publish.message_id,
			evt->param.publish.message.topic.qos);
		LOG_INF("   ├── topic: %.*s",
			evt->param.publish.message.topic.topic.size,
			evt->param.publish.message.topic.topic.utf8);

		while (len) {
			bytes_read = mqtt_read_publish_payload(&client_ctx,
					data,
					len >= sizeof(data) - 1 ?
					sizeof(data) - 1 : len);
			if (bytes_read < 0 && bytes_read != -EAGAIN) {
				LOG_ERR("failure to read payload");
				break;
			}

			data[bytes_read] = '\0';
			LOG_INF("   └── payload: %s", data);
			len -= bytes_read;
		}

		for (int i = 0; i < number_of_subscriptions; i++) {
			if (strncmp(subscriptions[i].topic,
				    evt->param.publish.message.topic.topic.utf8,
				    evt->param.publish.message.topic.topic.size) == 0) {
				subscriptions[i].callback(data);
				break;
			}
		}
		break;

	case MQTT_EVT_PINGRESP:
		openthread_request_normal_latency("MQTT_EVT_PINGRESP");

		LOG_INF("PINGRESP");
		LOG_INF("└── 🦴 feed watchdog");
		wdt_feed(wdt, wdt_channel_id);
		break;

	default:
		LOG_WRN("Unhandled MQTT event %d", evt->type);
		break;
	}
}

static int subscribe(struct mqtt_client *client, const char *topic)
{
	int ret;
	struct mqtt_topic subs_topic;
	struct mqtt_subscription_list subs_list;

	subs_topic.topic.utf8 = topic;
	subs_topic.topic.size = strlen(topic);
	subs_topic.qos = MQTT_QOS_0_AT_MOST_ONCE;
	subs_list.list = &subs_topic;
	subs_list.list_count = 1U;
	subs_list.message_id = 1U;

	openthread_request_low_latency("mqtt_subscribe");

	ret = mqtt_subscribe(client, &subs_list);
	if (ret) {
		openthread_request_normal_latency("mqtt_subscribe error");
		LOG_ERR("Failed on topic %s", topic);
		return ret;
	}

	return 0;
}

static void keepalive(struct k_work *work)
{
	int ret;

	LOG_INF("🤖 mqtt keepalive");

	if (!is_mqtt_connected()) {
		ret = connect_to_server();
		if (ret < 0) {
			LOG_ERR("Failed to connect to server");
			goto out;
		}
	}

	if (client_ctx.unacked_ping) {
		LOG_WRN("🤔 MQTT ping not acknowledged: %d",
			client_ctx.unacked_ping);
	}

	openthread_request_low_latency("mqtt_ping");

	ret = mqtt_ping(&client_ctx);
	if (ret < 0) {
		openthread_request_normal_latency("mqtt_ping error");
		LOG_ERR("mqtt_ping (%d)", ret);
	}

out:
	k_work_reschedule(&keepalive_work, K_SECONDS(client_ctx.keepalive));
}

static void mqtt_receive_thread_function(void)
{
	int rc;

	while (1) {
		wait_for_mqtt_connected();
		if (poll_socket(SYS_FOREVER_MS)) {
			LOG_INF("mqtt_receive_thread: mqtt_input()");
			rc = mqtt_input(&client_ctx);
			if (rc < 0) {
				LOG_WRN("⚠️  mqtt_input (%d)", rc);
			}
		}
	}
}

K_THREAD_DEFINE(mqtt_receive_thread, CONFIG_APP_MQTT_RECEIVE_THREAD_STACK_SIZE,
		mqtt_receive_thread_function, NULL, NULL, NULL,
		K_LOWEST_APPLICATION_THREAD_PRIO, 0, SYS_FOREVER_MS);


#define MQTT_CONNECT_TIMEOUT_MS	1000
#define MQTT_ABORT_TIMEOUT_MS	5000
static int try_to_connect(struct mqtt_client *client)
{
	uint8_t retries = 3U;
	int rc;

	LOG_INF("attempting to connect");

	while (retries--) {
		client_init(client);

		openthread_request_low_latency("mqtt_connect");

		rc = mqtt_connect(client);
		if (rc) {
			openthread_request_normal_latency("mqtt_connect error");
			LOG_ERR("mqtt_connect failed %d", rc);
			continue;
		}

		// This is after `mqtt_connect()` so can get the socket descriptor
		prepare_fds(client);

		rc = poll_socket(MQTT_CONNECT_TIMEOUT_MS);
		if (rc < 0) {
			openthread_request_normal_latency("mqtt_connect error");
			goto abort;
		}

		mqtt_input(client);

		if (is_mqtt_connected()) {
			// If we are reconnecting and so a keepalive work is
			// already pending, this function will replace the
			// currently pending one.
			// 
			// https://docs.zephyrproject.org/latest/kernel/services/threads/workqueue.html#scheduling-a-delayable-work-item
			k_work_reschedule(&keepalive_work,
					  K_SECONDS(client->keepalive));
			// Does nothing if thread is already started.
			// https://github.com/zephyrproject-rtos/zephyr/blob/cdebe6ef711ffbd08b5faad48b955fdd077e00fc/kernel/sched.c#L658C37-L658C37
			k_thread_start(mqtt_receive_thread);
			return 0;
		}

abort:
		mqtt_abort(client);
		poll_socket(MQTT_ABORT_TIMEOUT_MS);
	}

	return -EINVAL;
}

#if defined(CONFIG_DNS_RESOLVER)
static int get_mqtt_broker_addrinfo(void)
{
	int retries = 3;
	int rc = -EINVAL;

	LOG_INF("resolving server address");

	while (retries--) {
		hints.ai_family = AF_INET6;
		hints.ai_socktype = SOCK_STREAM;
		hints.ai_protocol = 0;

		openthread_request_low_latency("getaddrinfo");

		// Return value:
		// zephyr/include/zephyr/net/dns_resolve.h
		// enum dns_resolve_status
		rc = getaddrinfo(CONFIG_APP_MQTT_SERVER_HOSTNAME,
				       STRINGIFY(CONFIG_APP_MQTT_SERVER_PORT),
				       &hints, &haddr);

		openthread_request_normal_latency("getaddrinfo done");

		if (rc == 0) {
			char atxt[INET6_ADDRSTRLEN] = { 0 };

			LOG_INF("DNS resolved for %s:%d",
			CONFIG_APP_MQTT_SERVER_HOSTNAME,
			CONFIG_APP_MQTT_SERVER_PORT);

			assert(haddr->ai_addr->sa_family == AF_INET6);

			inet_ntop(
			    AF_INET6,
			    &((const struct sockaddr_in6 *)haddr->ai_addr)->sin6_addr,
			    atxt, sizeof(atxt));

			LOG_INF("└── address: %s", atxt);

			return 0;
		}

		LOG_WRN("DNS not resolved for %s:%d (%d), retrying",
			CONFIG_APP_MQTT_SERVER_HOSTNAME,
			CONFIG_APP_MQTT_SERVER_PORT,
			rc);

		k_sleep(K_MSEC(200));
	}

	return rc;
}
#endif

static int connect_to_server(void)
{
	int rc = -EINVAL;

	LOG_INF("🔌 connect to server");

#if defined(CONFIG_DNS_RESOLVER)
	rc = get_mqtt_broker_addrinfo();
	if (rc) {
		return rc;
	}
#endif

	rc = try_to_connect(&client_ctx);
	if (rc) {
		return rc;
	}

	LOG_INF("mqtt keepalive: %ds", client_ctx.keepalive);

	return 0;
}

int mqtt_watchdog_init(const struct device *watchdog, int channel_id)
{
	wdt = watchdog;
	wdt_channel_id = channel_id;

	return 0;
}

int mqtt_publish_to_topic(const char *topic, char *payload, bool retain)
{
	int ret;
	struct mqtt_publish_param param;

	LOG_INF("📤 %s", topic);
	LOG_INF("   └── payload: %s", payload);

	// QOS 1 to receive an puback
	param.message.topic.qos = MQTT_QOS_1_AT_LEAST_ONCE;
	param.message.topic.topic.utf8 = (uint8_t *)topic;
	param.message.topic.topic.size = strlen(topic);
	param.message.payload.data = payload;
	param.message.payload.len = strlen(payload);
	param.message_id = sys_rand32_get();
	param.dup_flag = 0U;
	param.retain_flag = retain ? 1U : 0U;

	if (!is_mqtt_connected()) {
		ret = connect_to_server();
		if (ret < 0) {
			return ret;
		}
	}

	openthread_request_low_latency("mqtt_publish");

	ret = mqtt_publish(&client_ctx, &param);
	if (ret < 0) {
		openthread_request_normal_latency("mqtt_publish error");
		LOG_ERR("mqtt_publish (%d)", ret);
		return ret;
	}

	return 0;
}

int mqtt_subscribe_to_topic(const struct mqtt_subscription *subs,
			    size_t nb_of_subs)
{
	int ret;

	if (!is_mqtt_connected()) {
		ret = connect_to_server();
		if (ret < 0) {
			return ret;
		}
	}

	subscriptions = subs;
	number_of_subscriptions = nb_of_subs;

	for (int i = 0; i < nb_of_subs; i++) {
		LOG_INF("subscribing to topic: %s", subs[i].topic);
		ret = subscribe(&client_ctx, subs[i].topic);	
		if (ret < 0) {
			LOG_ERR("Could not subscribe to topic");
			return ret;
		}	
	}

	return 0;
}

int mqtt_init(const char *dev_id,
	      const char *last_will_topic_string,
	      const char *last_will_message_string)
{
	int ret;

	device_id = dev_id;

	last_will_topic.topic.utf8 = last_will_topic_string;
	last_will_topic.topic.size = strlen(last_will_topic_string);
	last_will_topic.qos = MQTT_QOS_0_AT_MOST_ONCE;

	last_will_message.utf8 = last_will_message_string;
	last_will_message.size = strlen(last_will_message_string);

	if (!is_mqtt_connected()) {
		ret = connect_to_server();
		if (ret < 0) {
			return ret;
		}
	}

	return 0;
}
```

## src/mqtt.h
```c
#ifndef MQTT_H_
#define MQTT_H_

#include <zephyr/device.h>
#include <zephyr/net/net_ip.h>


struct mqtt_subscription {
	const char *topic;
	void (*callback)(const char *);
};

int mqtt_publish_to_topic(const char *topic, char *payload, bool retain);
int mqtt_subscribe_to_topic(const struct mqtt_subscription *subs,
			    size_t nb_of_subs);
int mqtt_watchdog_init(const struct device *watchdog, int channel_id);
int mqtt_init(const char *dev_id,
	      const char *last_will_topic_string,
	      const char *last_will_message_string);

#endif /* MQTT_H_ */
```

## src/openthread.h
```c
#ifndef OPENTHREAD_H_
#define OPENTHREAD_H_

void openthread_enable_ready_flag();
bool openthread_is_ready();

void openthread_request_low_latency(const char *reason);
void openthread_request_normal_latency(const char *reason);
void openthread_force_normal_latency(const char *reason);

int openthread_erase_persistent_info();
int openthread_my_start(void);
int openthread_wait_for_ready(void);

#endif /* OPENTHREAD_H_ */
```

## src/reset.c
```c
#include <zephyr/drivers/hwinfo.h>

#include <zephyr/logging/log.h>
LOG_MODULE_REGISTER(reset, LOG_LEVEL_DBG);


static const char *cause_to_string(uint32_t cause)
{
	switch (cause) {
	case RESET_PIN:
		return "pin";

	case RESET_SOFTWARE:
		return "software";

	case RESET_BROWNOUT:
		return "brownout";

	case RESET_POR:
		return "power-on reset";

	case RESET_WATCHDOG:
		return "watchdog";

	case RESET_DEBUG:
		return "debug";

	case RESET_SECURITY:
		return "security";

	case RESET_LOW_POWER_WAKE:
		return "low power wake-up";

	case RESET_CPU_LOCKUP:
		return "CPU lockup";

	case RESET_PARITY:
		return "parity error";

	case RESET_PLL:
		return "PLL error";

	case RESET_CLOCK:
		return "clock";

	case RESET_HARDWARE:
		return "hardware";

	case RESET_USER:
		return "user";

	case RESET_TEMPERATURE:
		return "temperature";

	default:
		return "unknown";
	}
}

static void print_all_reset_causes(uint32_t cause)
{
	for (uint32_t cause_mask = 1; cause_mask; cause_mask <<= 1) {
		if (cause & cause_mask) {
			LOG_INF("✨ reset cause: %s",
				    cause_to_string(cause & cause_mask));
		}
	}
}

int show_reset_cause(void)
{
	int ret;
	uint32_t cause;

	ret = hwinfo_get_reset_cause(&cause);
	if (ret == -ENOTSUP) {
		LOG_ERR("reset cause: not supported by hardware");
		return ret;
	} else if (ret != 0) {
		LOG_ERR("reset cause: error reading the cause [%d]", ret);
		return ret;
	}

	if (cause != 0) {
		print_all_reset_causes(cause);
	} else {
		LOG_INF("no reset cause set");
	}

	return cause;
}

int clear_reset_cause(void)
{
	int ret;

	ret = hwinfo_clear_reset_cause();
	if (ret == -ENOTSUP) {
		LOG_ERR("Reset cause clear not supported by hardware");
	} else if (ret != 0) {
		LOG_ERR("Error clearing the reset causes [%d]", ret);
		return ret;
	}

	return 0;
}

bool is_reset_cause_watchdog(uint32_t cause)
{
	return cause & RESET_WATCHDOG;
}

bool is_reset_cause_button(uint32_t cause)
{
	return cause & RESET_PIN;
}

bool is_reset_cause_software(uint32_t cause)
{
	return cause & RESET_SOFTWARE;
}
```

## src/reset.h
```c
#ifndef RESET_H_
#define RESET_H_

int show_reset_cause(void);
int clear_reset_cause(void);
bool is_reset_cause_watchdog(uint32_t cause);
bool is_reset_cause_button(uint32_t cause);
bool is_reset_cause_software(uint32_t cause);

#endif /* RESET_H_ */
```
